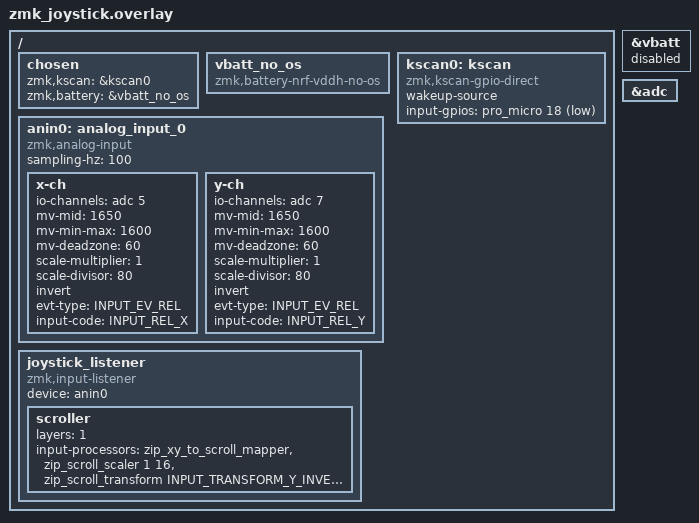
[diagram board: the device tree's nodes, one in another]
/*
 * Copyright (c) 2025 FredForte
 *
 * SPDX-License-Identifier: MIT
 */

#include <zephyr/dt-bindings/input/input-event-codes.h>
/* Reference: https://docs.zephyrproject.org/apidoc/latest/group__input__events.html */

#include <dt-bindings/zmk/input_transform.h>
#include <input/processors.dtsi>

/ {
    chosen {
        zmk,kscan = &kscan0;
        zmk,battery = &vbatt_no_os;
    };

    /*
     * Replace nice!nano v2's default vbatt sensor (which uses SAADC oversampling = 4)
     * with an oversampling-free VDDH sensor so 60-second battery polling does not
     * lock up the shared nRF52840 SAADC peripheral.
     */
    vbatt_no_os: vbatt_no_os {
        compatible = "zmk,battery-nrf-vddh-no-os";
    };

    /*
     * Direct GPIO input for the joystick module's built-in push button (SW).
     * Wire SW between nice!nano v2 pin 115 (P1.15 / Pro Micro D18) and GND.
     */
    kscan0: kscan {
        compatible = "zmk,kscan-gpio-direct";
        wakeup-source;
        input-gpios
            = <&pro_micro 18 (GPIO_ACTIVE_LOW | GPIO_PULL_UP)>
            ;
    };
};

&vbatt {
    status = "disabled";
};

&adc {
    status = "okay";
};

/ {
    anin0: analog_input_0 {
        compatible = "zmk,analog-input";
        sampling-hz = <100>;
        x-ch {
            io-channels = <&adc 5>; /* nice!nano v2 pin 029 (P0.29 / AIN5) */
            mv-mid = <1650>;        /* ~3.3V / 2 resting midpoint in millivolts */
            mv-min-max = <1600>;    /* full-scale +/- deflection in millivolts */
            mv-deadzone = <60>;     /* ignore +/-60 mV resting drift/jitter */
            scale-multiplier = <1>;
            scale-divisor = <80>;   /* scale mV to smooth cursor steps (0..~19 px/tick) */
            invert;
            evt-type = <INPUT_EV_REL>;
            input-code = <INPUT_REL_X>;
        };
        y-ch {
            io-channels = <&adc 7>; /* nice!nano v2 pin 031 (P0.31 / AIN7) */
            mv-mid = <1650>;        /* ~3.3V / 2 resting midpoint in millivolts */
            mv-min-max = <1600>;    /* full-scale +/- deflection in millivolts */
            mv-deadzone = <60>;     /* ignore +/-60 mV resting drift/jitter */
            scale-multiplier = <1>;
            scale-divisor = <80>;   /* scale mV to smooth cursor steps (0..~19 px/tick) */
            invert;
            evt-type = <INPUT_EV_REL>;
            input-code = <INPUT_REL_Y>;
        };
    };

    joystick_listener {
        compatible = "zmk,input-listener";
        device = <&anin0>;

        /*
         * Layer 1 (scroll_layer): switch joystick from cursor movement to
         * vertical/horizontal scrolling while holding SW (or any &mo 1 key).
         */
        scroller {
            layers = <1>;
            input-processors
                = <&zip_xy_to_scroll_mapper>
                , <&zip_scroll_scaler 1 16>
                , <&zip_scroll_transform INPUT_TRANSFORM_Y_INVERT>
                ;
        };
    };
};
